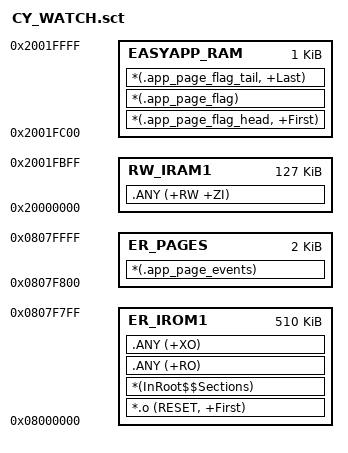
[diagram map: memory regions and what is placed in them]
; *************************************************************
; *** Scatter-Loading Description File   (STM32F411CEU6/AC6) ***
; *** Flash 512KB @0x08000000 , RAM 128KB @0x20000000        ***
; *************************************************************

LR_IROM1 0x08000000 0x0007F800  {    ; 主程序 0x08000000~0x0807F7FF
  ER_IROM1 0x08000000 0x0007F800  {
   *.o (RESET, +First)               ; 向量表必须占住 0x08000000
   *(InRoot$$Sections)
   .ANY (+RO)
   .ANY (+XO)
  }
  ; RW_IRAM1 与 EASYAPP_RAM 首尾相接, 两块相加恒为 0x20000(128KB), 改一块要同步另一块
  RW_IRAM1 0x20000000 0x0001FC00  {  ; RW data
   .ANY (+RW +ZI)
  }
  ; EasyAPP 页标志数组: 三段必须按 head → 各页 → tail 连续摆放.
  ; 分发器靠指针自增从 head 走到 tail, 顺序错了会静默派发错页
  EASYAPP_RAM 0x2001FC00 0x00000400  {
    *(.app_page_flag_head, +First)
    *(.app_page_flag)                ; easyapp_page_flag_<name>, 每个 8B
    *(.app_page_flag_tail, +Last)
  }
}

; 页表独占一个加载区, 让 load == exec: 就地存放, 开机不用拷
LR_PAGES 0x0807F800 0x00000800  {
  ER_PAGES 0x0807F800 0x00000800  {
    *(.app_page_events)              ; easyapp_page_<name>, 以 PAGE_EVENT_TAIL 定界
  }
}
